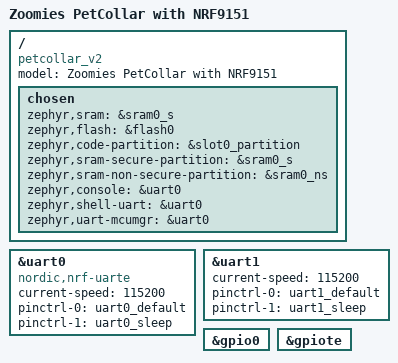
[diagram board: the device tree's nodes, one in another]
/dts-v1/;
#include <nordic/nrf9151_laca.dtsi>
#include "petcollar_v2-pinctrl.dtsi"
#include "petcollar_v2-partitioning.dtsi"

/ {
    model = "Zoomies PetCollar with NRF9151";
	compatible = "petcollar_v2";

	chosen {
		zephyr,sram = &sram0_s;
		zephyr,flash = &flash0;
		zephyr,code-partition = &slot0_partition;
		zephyr,sram-secure-partition = &sram0_s;
		zephyr,sram-non-secure-partition = &sram0_ns;
        zephyr,console = &uart0;
		zephyr,shell-uart = &uart0;
		zephyr,uart-mcumgr = &uart0;
	};
};

&uart0 {
	compatible = "nordic,nrf-uarte";
	status = "okay";
	current-speed = <115200>;
	pinctrl-0 = <&uart0_default>;
	pinctrl-1 = <&uart0_sleep>;
	pinctrl-names = "default", "sleep";
};

&uart1 {
	status = "okay";
	current-speed = <115200>;
	pinctrl-0 = <&uart1_default>;
	pinctrl-1 = <&uart1_sleep>;
	pinctrl-names = "default", "sleep";
};

&gpio0 {
	status = "okay";
};

&gpiote {
	status = "okay";
};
